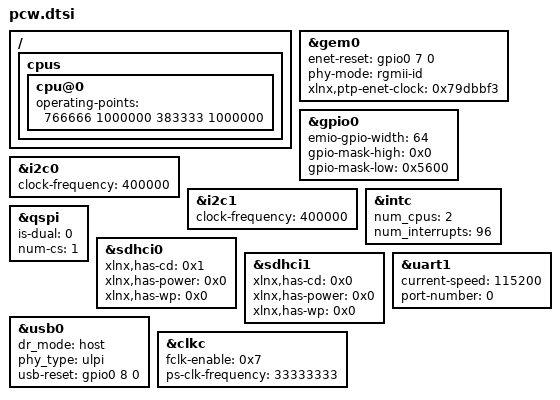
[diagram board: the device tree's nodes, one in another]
/*
 * CAUTION: This file is automatically generated by Xilinx.
 * Version: HSI 2015.4
 * Today is: Fri Nov 24 15:27:34 2017
*/


/ {
	cpus {
		cpu@0 {
			operating-points = <766666 1000000 383333 1000000>;
		};
	};
};
&gem0 {
	enet-reset = <&gpio0 7 0>;
	phy-mode = "rgmii-id";
	status = "okay";
	xlnx,ptp-enet-clock = <0x79dbbf3>;
};
&gpio0 {
	emio-gpio-width = <64>;
	gpio-mask-high = <0x0>;
	gpio-mask-low = <0x5600>;
};
&i2c0 {
	clock-frequency = <400000>;
	status = "okay";
};
&i2c1 {
	clock-frequency = <400000>;
	status = "okay";
};
&intc {
	num_cpus = <2>;
	num_interrupts = <96>;
};
&qspi {
	is-dual = <0>;
	num-cs = <1>;
	status = "okay";
};
&sdhci0 {
	status = "okay";
	xlnx,has-cd = <0x1>;
	xlnx,has-power = <0x0>;
	xlnx,has-wp = <0x0>;
};
&sdhci1 {
	status = "okay";
	xlnx,has-cd = <0x0>;
	xlnx,has-power = <0x0>;
	xlnx,has-wp = <0x0>;
};
&uart1 {
	current-speed = <115200>;
	device_type = "serial";
	port-number = <0>;
	status = "okay";
};
&usb0 {
	dr_mode = "host";
	phy_type = "ulpi";
	status = "okay";
	usb-reset = <&gpio0 8 0>;
};
&clkc {
	fclk-enable = <0x7>;
	ps-clk-frequency = <33333333>;
};
